# STM32H7A3x register map
File version: 1.8
CPU: CM7 r0p1, little endian, MPU, FPU, 4 interrupt priority bits
Registers are 32-bit, read-write, reset 0x0 unless marked. A register's access mark holds for its fields unless they carry their own. Offsets are from the block's base; [hi:lo] are bit positions; {n}, {i} and the like mark numbered series.

## ADC12_Common — Analog-to-Digital Converter
Base 0x40022300
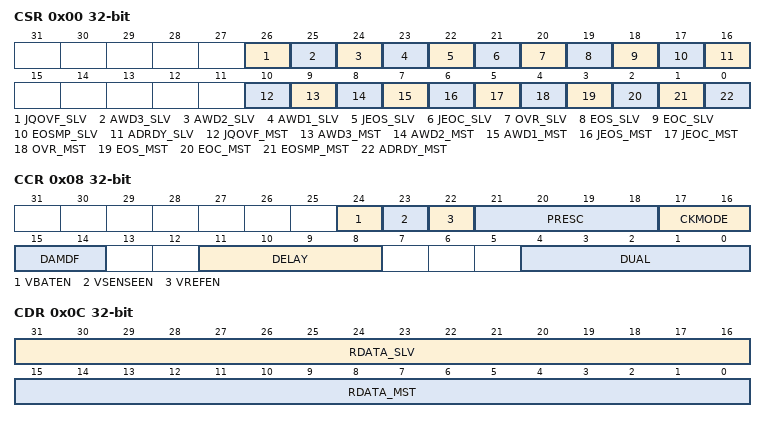
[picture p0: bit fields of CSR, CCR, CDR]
0x00 CSR ro — ADC Common status register
  [26] JQOVF_SLV — Injected Context Queue Overflow flag of the slave ADC
  [25] AWD3_SLV — Analog watchdog 3 flag of the slave ADC
  [24] AWD2_SLV — Analog watchdog 2 flag of the slave ADC
  [23] AWD1_SLV — Analog watchdog 1 flag of the slave ADC
  [22] JEOS_SLV — End of injected sequence flag of the slave ADC
  [21] JEOC_SLV — End of injected conversion flag of the slave ADC
  [20] OVR_SLV — Overrun flag of the slave ADC
  [19] EOS_SLV — End of regular sequence flag of the slave ADC
  [18] EOC_SLV — End of regular conversion of the slave ADC
  [17] EOSMP_SLV — End of Sampling phase flag of the slave ADC
  [16] ADRDY_SLV — Slave ADC ready
  [10] JQOVF_MST — Injected Context Queue Overflow flag of the master ADC
  [9] AWD3_MST — Analog watchdog 3 flag of the master ADC
  [8] AWD2_MST — Analog watchdog 2 flag of the master ADC
  [7] AWD1_MST — Analog watchdog 1 flag of the master ADC
  [6] JEOS_MST — End of injected sequence flag of the master ADC
  [5] JEOC_MST — End of injected conversion flag of the master ADC
  [4] OVR_MST — Overrun flag of the master ADC
  [3] EOS_MST — End of regular sequence flag of the master ADC
  [2] EOC_MST — End of regular conversion of the master ADC
  [1] EOSMP_MST — End of Sampling phase flag of the master ADC
  [0] ADRDY_MST — Master ADC ready
0x08 CCR — ADC common control register
  [24] VBATEN — VBAT enable
  [23] VSENSEEN — Temperature sensor enable
  [22] VREFEN — VREFINT enable
  [21:18] PRESC — ADC prescaler
  [17:16] CKMODE — ADC clock mode
  [15:14] DAMDF — Dual ADC Mode Data Format
  [11:8] DELAY — Delay between 2 sampling phases
  [4:0] DUAL — Dual ADC mode selection
0x0C CDR ro — ADC common regular data register for dual and triple modes
  [31:16] RDATA_SLV — Regular data of the slave ADC
  [15:0] RDATA_MST — Regular data of the master ADC

## DMAMUX1 — DMAMUX
Base 0x40020800
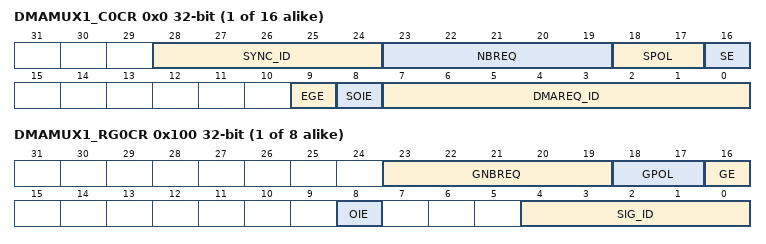
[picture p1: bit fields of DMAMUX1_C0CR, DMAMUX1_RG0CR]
{0x0+4i} DMAMUX1_C{i}CR (i=0..15) — DMAMux - DMA request line multiplexer channel x control register
  [28:24] SYNC_ID — Synchronization input selected
  [23:19] NBREQ — Number of DMA requests to forward Defines the number of DMA requests forwarded before output event is generated. In synchronous mode, it also defines the number of DMA requests to forward after a synchronization event, then stop forwarding. The actual number of DMA requests forwarded is NBREQ+1. Note: This field can only be written when both SE and EGE bits are reset.
  [18:17] SPOL — Synchronization event type selector Defines the synchronization event on the selected synchronization input:
  [16] SE — Synchronous operating mode enable/disable
  [9] EGE — Event generation enable/disable
  [8] SOIE — Interrupt enable at synchronization event overrun
  [7:0] DMAREQ_ID — Input DMA request line selected
0x80 DMAMUX1_CSR ro — DMAMUX request line multiplexer interrupt channel status register
  [15:0] SOF — Synchronization overrun event flag
0x84 DMAMUX1_CFR wo — DMAMUX request line multiplexer interrupt clear flag register
  [15:0] CSOF — Clear synchronization overrun event flag
{0x100+4i} DMAMUX1_RG{i}CR (i=0..7) — DMAMux - DMA request generator channel x control register
  [23:19] GNBREQ — Number of DMA requests to generate Defines the number of DMA requests generated after a trigger event, then stop generating. The actual number of generated DMA requests is GNBREQ+1. Note: This field can only be written when GE bit is reset.
  [18:17] GPOL — DMA request generator trigger event type selection Defines the trigger event on the selected DMA request trigger input
  [16] GE — DMA request generator channel enable/disable
  [8] OIE — Interrupt enable at trigger event overrun
  [4:0] SIG_ID — DMA request trigger input selected
0x140 DMAMUX1_RGSR ro — DMAMux - DMA request generator status register
  [7:0] OF — Trigger event overrun flag The flag is set when a trigger event occurs on DMA request generator channel x, while the DMA request generator counter value is lower than GNBREQ. The flag is cleared by writing 1 to the corresponding COFx bit in DMAMUX_RGCFR register.
0x144 DMAMUX1_RGCFR wo — DMAMux - DMA request generator clear flag register
  [7:0] COF — Clear trigger event overrun flag Upon setting, this bit clears the corresponding overrun flag OFx in the DMAMUX_RGCSR register.
